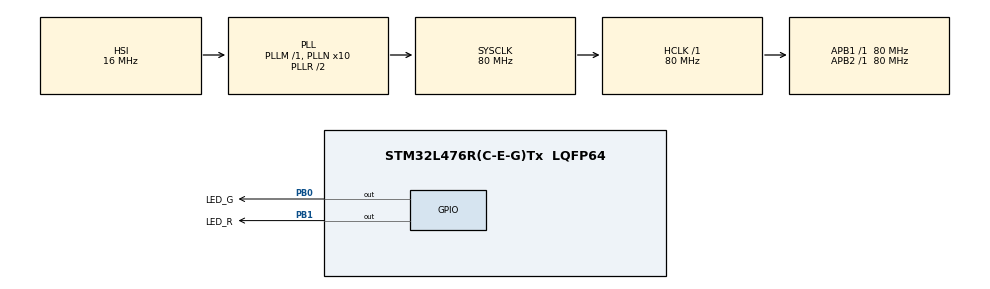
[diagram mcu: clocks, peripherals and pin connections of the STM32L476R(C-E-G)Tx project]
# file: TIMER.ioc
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Mcu.Family=STM32L4
Mcu.Name=STM32L476R(C-E-G)Tx
Mcu.Package=LQFP64
NVIC.PriorityGroup=NVIC_PRIORITYGROUP_4
NVIC.TIM1_UP_TIM16_IRQn=true\:1\:0\:true\:false\:true\:true\:true\:true
PA13\ (JTMS-SWDIO).Mode=Serial_Wire
PA13\ (JTMS-SWDIO).Signal=SYS_JTMS-SWDIO
PA14\ (JTCK-SWCLK).Mode=Serial_Wire
PA14\ (JTCK-SWCLK).Signal=SYS_JTCK-SWCLK
PB0.GPIO_Label=LED_G
PB0.Signal=GPIO_Output
PB1.GPIO_Label=LED_R
PB1.Signal=GPIO_Output
ProjectManager.HeapSize=0x200
ProjectManager.StackSize=0x400
ProjectManager.TargetToolchain=MDK-ARM V5.32
RCC.ADCFreq_Value=64000000
RCC.AHBFreq_Value=80000000
RCC.APB1Freq_Value=80000000
RCC.APB1TimFreq_Value=80000000
RCC.APB2Freq_Value=80000000
RCC.APB2TimFreq_Value=80000000
RCC.CortexFreq_Value=80000000
RCC.HCLKFreq_Value=80000000
RCC.HSE_VALUE=8000000
RCC.HSI_VALUE=16000000
RCC.LSE_VALUE=32768
RCC.MSI_VALUE=4000000
RCC.PLLN=10
RCC.PLLSourceVirtual=RCC_PLLSOURCE_HSI
RCC.SYSCLKFreq_VALUE=80000000
RCC.SYSCLKSource=RCC_SYSCLKSOURCE_PLLCLK
RCC.USBFreq_Value=64000000
RCC.VCOOutputFreq_Value=160000000
TIM1.Period=499
TIM1.Prescaler=7999
TIM3.Prescaler=80
VP_TIM1_VS_ClockSourceINT.Mode=Internal
VP_TIM3_VS_ClockSourceINT.Mode=Internal
board=custom

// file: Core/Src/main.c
/* USER CODE BEGIN Header */
/**
  ******************************************************************************
  * @file           : main.c
  * @brief          : Main program body
  ******************************************************************************
  * @attention
  *
  * Copyright (c) 2026 STMicroelectronics.
  * All rights reserved.
  *
  * This software is licensed under terms that can be found in the LICENSE file
  * in the root directory of this software component.
  * If no LICENSE file comes with this software, it is provided AS-IS.
  *
  ******************************************************************************
  */
/* USER CODE END Header */
#include "main.h"

TIM_HandleTypeDef htim1;
TIM_HandleTypeDef htim3;

void SystemClock_Config(void);
static void MX_GPIO_Init(void);
static void MX_TIM1_Init(void);
static void MX_TIM3_Init(void);

/* USER CODE BEGIN 0 */
void delay_us(uint16_t us)
{
	htim3.Instance->CNT = 0;
	HAL_TIM_Base_Start(&htim3);
	while(htim3.Instance->CNT < us);
	HAL_TIM_Base_Stop(&htim3);
}

void delay_ms(uint16_t ms)
{
	for (uint16_t i = 0; i < ms; i++)
	{
		delay_us(1000);
	}
}

void HAL_TIM_PeriodElapsedCallback(TIM_HandleTypeDef *htim)
{
//  	HAL_GPIO_TogglePin(LED_R_GPIO_Port, LED_R_Pin);

}
/* USER CODE END 0 */

int main(void)
{

  /* MCU Configuration--------------------------------------------------------*/

  /* Reset of all peripherals, Initializes the Flash interface and the Systick. */
  HAL_Init();

  /* Configure the system clock */
  SystemClock_Config();

  /* Initialize all configured peripherals */
  MX_GPIO_Init();
  MX_TIM1_Init();
  MX_TIM3_Init();
  /* USER CODE BEGIN 2 */
	HAL_TIM_Base_Start_IT(&htim1);
  /* USER CODE END 2 */

  /* Infinite loop */
  while (1)
  {
		delay_us(10000);
		HAL_GPIO_TogglePin(LED_R_GPIO_Port, LED_R_Pin);
		delay_ms(1000);
		HAL_GPIO_TogglePin(LED_G_GPIO_Port, LED_G_Pin);

//
  }
}

void SystemClock_Config(void)
{
  RCC_OscInitTypeDef RCC_OscInitStruct = {0};
  RCC_ClkInitTypeDef RCC_ClkInitStruct = {0};

  /** Configure the main internal regulator output voltage
  */
  if (HAL_PWREx_ControlVoltageScaling(PWR_REGULATOR_VOLTAGE_SCALE1) != HAL_OK)
  {
    Error_Handler();
  }

  /** Initializes the RCC Oscillators according to the specified parameters
  * in the RCC_OscInitTypeDef structure.
  */
  RCC_OscInitStruct.OscillatorType = RCC_OSCILLATORTYPE_HSI;
  RCC_OscInitStruct.HSIState = RCC_HSI_ON;
  RCC_OscInitStruct.HSICalibrationValue = RCC_HSICALIBRATION_DEFAULT;
  RCC_OscInitStruct.PLL.PLLState = RCC_PLL_ON;
  RCC_OscInitStruct.PLL.PLLSource = RCC_PLLSOURCE_HSI;
  RCC_OscInitStruct.PLL.PLLM = 1;
  RCC_OscInitStruct.PLL.PLLN = 10;
  RCC_OscInitStruct.PLL.PLLP = RCC_PLLP_DIV7;
  RCC_OscInitStruct.PLL.PLLQ = RCC_PLLQ_DIV2;
  RCC_OscInitStruct.PLL.PLLR = RCC_PLLR_DIV2;
  if (HAL_RCC_OscConfig(&RCC_OscInitStruct) != HAL_OK)
  {
    Error_Handler();
  }

  /** Initializes the CPU, AHB and APB buses clocks
  */
  RCC_ClkInitStruct.ClockType = RCC_CLOCKTYPE_HCLK|RCC_CLOCKTYPE_SYSCLK
                              |RCC_CLOCKTYPE_PCLK1|RCC_CLOCKTYPE_PCLK2;
  RCC_ClkInitStruct.SYSCLKSource = RCC_SYSCLKSOURCE_PLLCLK;
  RCC_ClkInitStruct.AHBCLKDivider = RCC_SYSCLK_DIV1;
  RCC_ClkInitStruct.APB1CLKDivider = RCC_HCLK_DIV1;
  RCC_ClkInitStruct.APB2CLKDivider = RCC_HCLK_DIV1;

  if (HAL_RCC_ClockConfig(&RCC_ClkInitStruct, FLASH_LATENCY_4) != HAL_OK)
  {
    Error_Handler();
  }
}

static void MX_TIM1_Init(void)
{

  TIM_ClockConfigTypeDef sClockSourceConfig = {0};
  TIM_MasterConfigTypeDef sMasterConfig = {0};

  htim1.Instance = TIM1;
  htim1.Init.Prescaler = 7999;
  htim1.Init.CounterMode = TIM_COUNTERMODE_UP;
  htim1.Init.Period = 499;
  htim1.Init.ClockDivision = TIM_CLOCKDIVISION_DIV1;
  htim1.Init.RepetitionCounter = 0;
  htim1.Init.AutoReloadPreload = TIM_AUTORELOAD_PRELOAD_DISABLE;
  if (HAL_TIM_Base_Init(&htim1) != HAL_OK)
  {
    Error_Handler();
  }
  sClockSourceConfig.ClockSource = TIM_CLOCKSOURCE_INTERNAL;
  if (HAL_TIM_ConfigClockSource(&htim1, &sClockSourceConfig) != HAL_OK)
  {
    Error_Handler();
  }
  sMasterConfig.MasterOutputTrigger = TIM_TRGO_RESET;
  sMasterConfig.MasterOutputTrigger2 = TIM_TRGO2_RESET;
  sMasterConfig.MasterSlaveMode = TIM_MASTERSLAVEMODE_DISABLE;
  if (HAL_TIMEx_MasterConfigSynchronization(&htim1, &sMasterConfig) != HAL_OK)
  {
    Error_Handler();
  }

}

static void MX_TIM3_Init(void)
{

  TIM_ClockConfigTypeDef sClockSourceConfig = {0};
  TIM_MasterConfigTypeDef sMasterConfig = {0};

  htim3.Instance = TIM3;
  htim3.Init.Prescaler = 80;
  htim3.Init.CounterMode = TIM_COUNTERMODE_UP;
  htim3.Init.Period = 65535;
  htim3.Init.ClockDivision = TIM_CLOCKDIVISION_DIV1;
  htim3.Init.AutoReloadPreload = TIM_AUTORELOAD_PRELOAD_DISABLE;
  if (HAL_TIM_Base_Init(&htim3) != HAL_OK)
  {
    Error_Handler();
  }
  sClockSourceConfig.ClockSource = TIM_CLOCKSOURCE_INTERNAL;
  if (HAL_TIM_ConfigClockSource(&htim3, &sClockSourceConfig) != HAL_OK)
  {
    Error_Handler();
  }
  sMasterConfig.MasterOutputTrigger = TIM_TRGO_RESET;
  sMasterConfig.MasterSlaveMode = TIM_MASTERSLAVEMODE_DISABLE;
  if (HAL_TIMEx_MasterConfigSynchronization(&htim3, &sMasterConfig) != HAL_OK)
  {
    Error_Handler();
  }

}

static void MX_GPIO_Init(void)
{
  GPIO_InitTypeDef GPIO_InitStruct = {0};

  /* GPIO Ports Clock Enable */
  __HAL_RCC_GPIOB_CLK_ENABLE();
  __HAL_RCC_GPIOA_CLK_ENABLE();

  /*Configure GPIO pin Output Level */
  HAL_GPIO_WritePin(GPIOB, LED_G_Pin|LED_R_Pin, GPIO_PIN_RESET);

  /*Configure GPIO pins : LED_G_Pin LED_R_Pin */
  GPIO_InitStruct.Pin = LED_G_Pin|LED_R_Pin;
  GPIO_InitStruct.Mode = GPIO_MODE_OUTPUT_PP;
  GPIO_InitStruct.Pull = GPIO_NOPULL;
  GPIO_InitStruct.Speed = GPIO_SPEED_FREQ_LOW;
  HAL_GPIO_Init(GPIOB, &GPIO_InitStruct);

}

void Error_Handler(void)
{
  __disable_irq();
  while (1)
  {
  }
}
